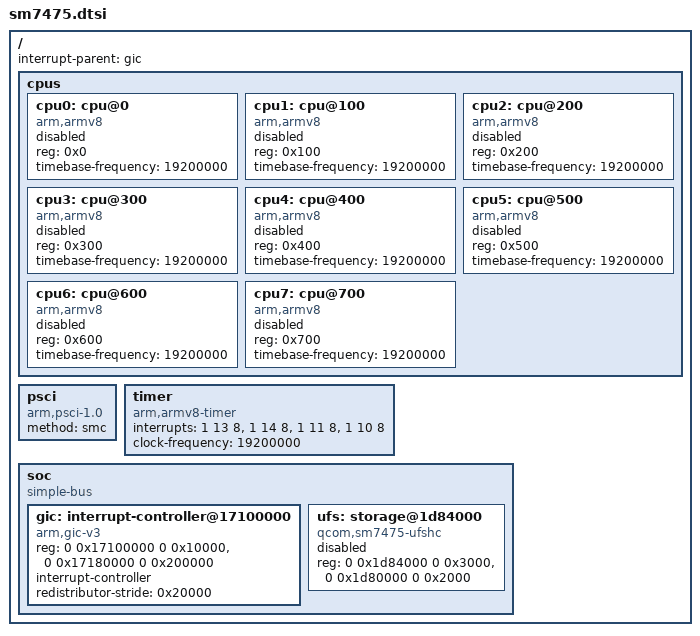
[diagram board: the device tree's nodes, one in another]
/ {
    #address-cells = <2>;
    #size-cells = <2>;
    interrupt-parent = <&gic>;
    cpus {
        #address-cells = <1>;
        #size-cells = <0>;
        cpu0: cpu@0 { device_type = "cpu"; compatible = "arm,armv8"; reg = <0x0>; timebase-frequency = <19200000>; status = "disabled"; };
        cpu1: cpu@100 { device_type = "cpu"; compatible = "arm,armv8"; reg = <0x100>; timebase-frequency = <19200000>; status = "disabled"; };
        cpu2: cpu@200 { device_type = "cpu"; compatible = "arm,armv8"; reg = <0x200>; timebase-frequency = <19200000>; status = "disabled"; };
        cpu3: cpu@300 { device_type = "cpu"; compatible = "arm,armv8"; reg = <0x300>; timebase-frequency = <19200000>; status = "disabled"; };
        cpu4: cpu@400 { device_type = "cpu"; compatible = "arm,armv8"; reg = <0x400>; timebase-frequency = <19200000>; status = "disabled"; };
        cpu5: cpu@500 { device_type = "cpu"; compatible = "arm,armv8"; reg = <0x500>; timebase-frequency = <19200000>; status = "disabled"; };
        cpu6: cpu@600 { device_type = "cpu"; compatible = "arm,armv8"; reg = <0x600>; timebase-frequency = <19200000>; status = "disabled"; };
        cpu7: cpu@700 { device_type = "cpu"; compatible = "arm,armv8"; reg = <0x700>; timebase-frequency = <19200000>; status = "disabled"; };
    };
    psci { compatible = "arm,psci-1.0"; method = "smc"; };
    timer { compatible = "arm,armv8-timer"; interrupts = <1 13 8>, <1 14 8>, <1 11 8>, <1 10 8>; clock-frequency = <19200000>; };
    soc {
        compatible = "simple-bus";
        #address-cells = <2>;
        #size-cells = <2>;
        ranges;
        gic: interrupt-controller@17100000 {
            compatible = "arm,gic-v3";
            reg = <0 0x17100000 0 0x10000>, <0 0x17180000 0 0x200000>;
            #interrupt-cells = <3>;
            #address-cells = <0>;
            interrupt-controller;
            redistributor-stride = /bits/ 64 <0x20000>;
        };
        ufs: storage@1d84000 {
            compatible = "qcom,sm7475-ufshc";
            reg = <0 0x1d84000 0 0x3000>, <0 0x1d80000 0 0x2000>;
            reg-names = "host", "phy";
            status = "disabled";
        };
    };
};
